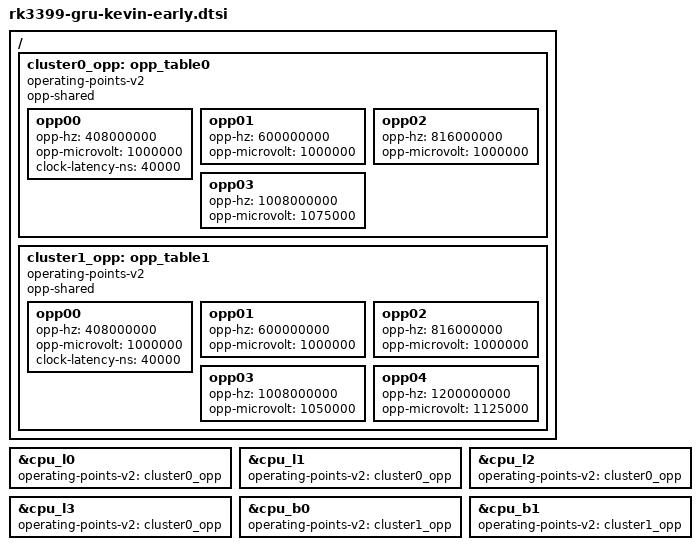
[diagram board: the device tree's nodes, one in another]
/*
 * Copyright (c) 2016 Fuzhou Rockchip Electronics Co., Ltd
 *
 * This file is dual-licensed: you can use it either under the terms
 * of the GPL or the X11 license, at your option. Note that this dual
 * licensing only applies to this file, and not this project as a
 * whole.
 *
 *  a) This library is free software; you can redistribute it and/or
 *     modify it under the terms of the GNU General Public License as
 *     published by the Free Software Foundation; either version 2 of the
 *     License, or (at your option) any later version.
 *
 *     This library is distributed in the hope that it will be useful,
 *     but WITHOUT ANY WARRANTY; without even the implied warranty of
 *     MERCHANTABILITY or FITNESS FOR A PARTICULAR PURPOSE.  See the
 *     GNU General Public License for more details.
 *
 * Or, alternatively,
 *
 *  b) Permission is hereby granted, free of charge, to any person
 *     obtaining a copy of this software and associated documentation
 *     files (the "Software"), to deal in the Software without
 *     restriction, including without limitation the rights to use,
 *     copy, modify, merge, publish, distribute, sublicense, and/or
 *     sell copies of the Software, and to permit persons to whom the
 *     Software is furnished to do so, subject to the following
 *     conditions:
 *
 *     The above copyright notice and this permission notice shall be
 *     included in all copies or substantial portions of the Software.
 *
 *     THE SOFTWARE IS PROVIDED "AS IS", WITHOUT WARRANTY OF ANY KIND,
 *     EXPRESS OR IMPLIED, INCLUDING BUT NOT LIMITED TO THE WARRANTIES
 *     OF MERCHANTABILITY, FITNESS FOR A PARTICULAR PURPOSE AND
 *     NONINFRINGEMENT. IN NO EVENT SHALL THE AUTHORS OR COPYRIGHT
 *     HOLDERS BE LIABLE FOR ANY CLAIM, DAMAGES OR OTHER LIABILITY,
 *     WHETHER IN AN ACTION OF CONTRACT, TORT OR OTHERWISE, ARISING
 *     FROM, OUT OF OR IN CONNECTION WITH THE SOFTWARE OR THE USE OR
 *     OTHER DEALINGS IN THE SOFTWARE.
 */

#include "rk3399-gru-kevin.dtsi"


/*
 * NOTE: this file exists only for the sake of early Kevin boards with early
 * (pre-ES2) silicon, because we require ~200mV extra voltage margin on the
 * CPU, due to voltage drop issues. New boards should have less drop, and new
 * silicon will be coming as well, with different power characteristics.
 */

/ {
	/*
	 * HACK: these are not validated by Rockchip. We need up to 200mV
	 * additional margin for early Kevin boards, so this table:
	 *  (a) adds 200mV to all voltage levels and
	 *  (b) drops OPPs that (after (a)) would potentially would exceed our
	 *      1.2V maximum (opp04 on the opp_table0)
	 * Didn't use 'regulator-microvolt-offset' property, since that has
	 * some bugs around enforcing the maximum for the regulator itself
	 * (TODO: should probably patch this upstream), and it also wouldn't
	 * allow us to clamp off any OPPs that are valid for the regulator but
	 * not for the CPU (i.e., voltage between the CPU max of 1.2V and the
	 * regulator max of 1.5V).
	 */
	cluster0_opp: opp_table0 {
		compatible = "operating-points-v2";
		opp-shared;

		opp00 {
			opp-hz = /bits/ 64 <408000000>;
			opp-microvolt = <1000000>;
			clock-latency-ns = <40000>;
		};
		opp01 {
			opp-hz = /bits/ 64 <600000000>;
			opp-microvolt = <1000000>;
		};
		opp02 {
			opp-hz = /bits/ 64 <816000000>;
			opp-microvolt = <1000000>;
		};
		opp03 {
			opp-hz = /bits/ 64 <1008000000>;
			opp-microvolt = <1075000>;
		};
	};

	cluster1_opp: opp_table1 {
		compatible = "operating-points-v2";
		opp-shared;

		opp00 {
			opp-hz = /bits/ 64 <408000000>;
			opp-microvolt = <1000000>;
			clock-latency-ns = <40000>;
		};
		opp01 {
			opp-hz = /bits/ 64 <600000000>;
			opp-microvolt = <1000000>;
		};
		opp02 {
			opp-hz = /bits/ 64 <816000000>;
			opp-microvolt = <1000000>;
		};
		opp03 {
			opp-hz = /bits/ 64 <1008000000>;
			opp-microvolt = <1050000>;
		};
		opp04 {
			opp-hz = /bits/ 64 <1200000000>;
			opp-microvolt = <1125000>;
		};
	};
};

&cpu_l0 {
	operating-points-v2 = <&cluster0_opp>;
};

&cpu_l1 {
	operating-points-v2 = <&cluster0_opp>;
};

&cpu_l2 {
	operating-points-v2 = <&cluster0_opp>;
};

&cpu_l3 {
	operating-points-v2 = <&cluster0_opp>;
};

&cpu_b0 {
	operating-points-v2 = <&cluster1_opp>;
};

&cpu_b1 {
	operating-points-v2 = <&cluster1_opp>;
};
